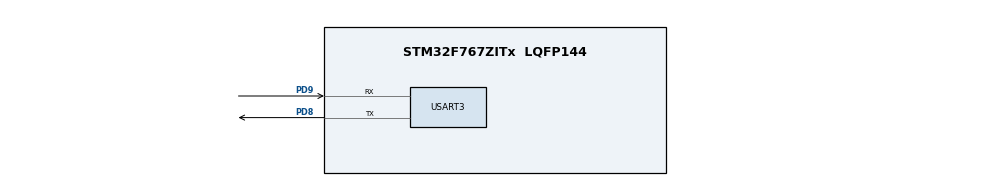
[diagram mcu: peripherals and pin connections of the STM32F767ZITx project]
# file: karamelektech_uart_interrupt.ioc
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Mcu.Family=STM32F7
Mcu.Name=STM32F767ZITx
Mcu.Package=LQFP144
NVIC.PriorityGroup=NVIC_PRIORITYGROUP_4
NVIC.USART3_IRQn=true\:0\:0\:false\:false\:true\:true\:true
PD8.Mode=Asynchronous
PD8.Signal=USART3_TX
PD9.Mode=Asynchronous
PD9.Signal=USART3_RX
ProjectManager.HeapSize=0x200
ProjectManager.StackSize=0x400
ProjectManager.TargetToolchain=MDK-ARM V5.27
RCC.HSE_VALUE=25000000
RCC.HSI_VALUE=16000000
RCC.LSE_VALUE=32768
RCC.USBFreq_Value=96000000
RCC.VCOOutputFreq_Value=192000000
USART3.VirtualMode-Asynchronous=VM_ASYNC
board=custom

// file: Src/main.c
/* USER CODE BEGIN Header */
/**
  ******************************************************************************
  * @file           : main.c
  * @brief          : Main program body
  ******************************************************************************
  * @attention
  *
  * <h2><center>&copy; Copyright (c) 2020 STMicroelectronics.
  * All rights reserved.</center></h2>
  *
  * This software component is licensed by ST under BSD 3-Clause license,
  * the "License"; You may not use this file except in compliance with the
  * License. You may obtain a copy of the License at:
  *                        opensource.org/licenses/BSD-3-Clause
  *
  ******************************************************************************
  */
/* USER CODE END Header */

#include "main.h"

UART_HandleTypeDef huart3;

void SystemClock_Config(void);
static void MX_GPIO_Init(void);
static void MX_USART3_UART_Init(void);

/* USER CODE BEGIN 0 */
uint8_t receiveBuffer[8];
/* USER CODE END 0 */

int main(void)
{

  /* MCU Configuration--------------------------------------------------------*/

  /* Reset of all peripherals, Initializes the Flash interface and the Systick. */
  HAL_Init();

  /* Configure the system clock */
  SystemClock_Config();

  /* Initialize all configured peripherals */
  MX_GPIO_Init();
  MX_USART3_UART_Init();
  /* USER CODE BEGIN 2 */
	HAL_UART_Transmit_IT(&huart3,"karamelek.tech UART Kesme Uygulamasi",sizeof("karamelek.tech UART Kesme Uygulamasi"));
	HAL_UART_Receive_IT(&huart3,receiveBuffer,sizeof(receiveBuffer));

  /* USER CODE END 2 */

  /* Infinite loop */
  while (1)
  {

  }
}

void SystemClock_Config(void)
{
  RCC_OscInitTypeDef RCC_OscInitStruct = {0};
  RCC_ClkInitTypeDef RCC_ClkInitStruct = {0};
  RCC_PeriphCLKInitTypeDef PeriphClkInitStruct = {0};

  /** Configure the main internal regulator output voltage
  */
  __HAL_RCC_PWR_CLK_ENABLE();
  __HAL_PWR_VOLTAGESCALING_CONFIG(PWR_REGULATOR_VOLTAGE_SCALE3);
  /** Initializes the CPU, AHB and APB busses clocks
  */
  RCC_OscInitStruct.OscillatorType = RCC_OSCILLATORTYPE_HSI;
  RCC_OscInitStruct.HSIState = RCC_HSI_ON;
  RCC_OscInitStruct.HSICalibrationValue = RCC_HSICALIBRATION_DEFAULT;
  RCC_OscInitStruct.PLL.PLLState = RCC_PLL_NONE;
  if (HAL_RCC_OscConfig(&RCC_OscInitStruct) != HAL_OK)
  {
    Error_Handler();
  }
  /** Initializes the CPU, AHB and APB busses clocks
  */
  RCC_ClkInitStruct.ClockType = RCC_CLOCKTYPE_HCLK|RCC_CLOCKTYPE_SYSCLK
                              |RCC_CLOCKTYPE_PCLK1|RCC_CLOCKTYPE_PCLK2;
  RCC_ClkInitStruct.SYSCLKSource = RCC_SYSCLKSOURCE_HSI;
  RCC_ClkInitStruct.AHBCLKDivider = RCC_SYSCLK_DIV1;
  RCC_ClkInitStruct.APB1CLKDivider = RCC_HCLK_DIV1;
  RCC_ClkInitStruct.APB2CLKDivider = RCC_HCLK_DIV1;

  if (HAL_RCC_ClockConfig(&RCC_ClkInitStruct, FLASH_LATENCY_0) != HAL_OK)
  {
    Error_Handler();
  }
  PeriphClkInitStruct.PeriphClockSelection = RCC_PERIPHCLK_USART3;
  PeriphClkInitStruct.Usart3ClockSelection = RCC_USART3CLKSOURCE_PCLK1;
  if (HAL_RCCEx_PeriphCLKConfig(&PeriphClkInitStruct) != HAL_OK)
  {
    Error_Handler();
  }
}

static void MX_USART3_UART_Init(void)
{

  huart3.Instance = USART3;
  huart3.Init.BaudRate = 115200;
  huart3.Init.WordLength = UART_WORDLENGTH_8B;
  huart3.Init.StopBits = UART_STOPBITS_1;
  huart3.Init.Parity = UART_PARITY_NONE;
  huart3.Init.Mode = UART_MODE_TX_RX;
  huart3.Init.HwFlowCtl = UART_HWCONTROL_NONE;
  huart3.Init.OverSampling = UART_OVERSAMPLING_16;
  huart3.Init.OneBitSampling = UART_ONE_BIT_SAMPLE_DISABLE;
  huart3.AdvancedInit.AdvFeatureInit = UART_ADVFEATURE_NO_INIT;
  if (HAL_UART_Init(&huart3) != HAL_OK)
  {
    Error_Handler();
  }

}

static void MX_GPIO_Init(void)
{

  /* GPIO Ports Clock Enable */
  __HAL_RCC_GPIOD_CLK_ENABLE();

}

void Error_Handler(void)
{
}

/************************ (C) COPYRIGHT STMicroelectronics *****END OF FILE****/
